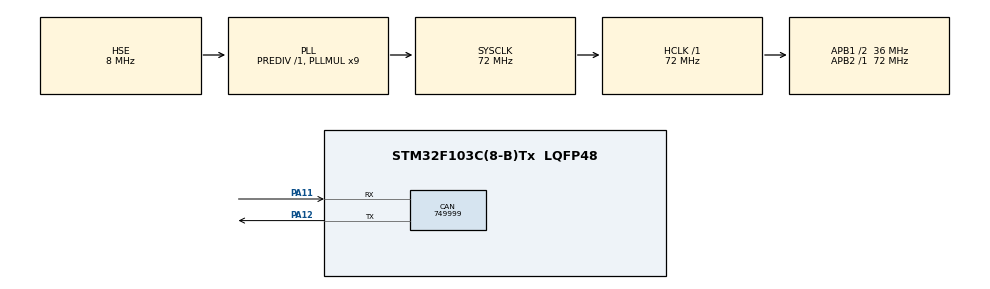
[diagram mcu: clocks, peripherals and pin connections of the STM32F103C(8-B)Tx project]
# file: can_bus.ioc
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CAN.CalculateBaudRate=749999
CAN.CalculateTimeBit=1333
CAN.CalculateTimeQuantum=444.44444444444446
Mcu.Family=STM32F1
Mcu.Name=STM32F103C(8-B)Tx
Mcu.Package=LQFP48
NVIC.CAN1_RX1_IRQn=true\:0\:0\:false\:false\:true\:true\:true\:true
NVIC.CAN1_SCE_IRQn=true\:0\:0\:false\:false\:true\:true\:true\:true
NVIC.PriorityGroup=NVIC_PRIORITYGROUP_4
NVIC.USB_HP_CAN1_TX_IRQn=true\:0\:0\:false\:false\:true\:true\:true\:true
NVIC.USB_LP_CAN1_RX0_IRQn=true\:0\:0\:false\:false\:true\:true\:true\:true
PA11.Mode=CAN_Activate
PA11.Signal=CAN_RX
PA12.Mode=CAN_Activate
PA12.Signal=CAN_TX
PC14-OSC32_IN.Mode=LSE-External-Oscillator
PC14-OSC32_IN.Signal=RCC_OSC32_IN
PC15-OSC32_OUT.Mode=LSE-External-Oscillator
PC15-OSC32_OUT.Signal=RCC_OSC32_OUT
PD0-OSC_IN.Mode=HSE-External-Oscillator
PD0-OSC_IN.Signal=RCC_OSC_IN
PD1-OSC_OUT.Mode=HSE-External-Oscillator
PD1-OSC_OUT.Signal=RCC_OSC_OUT
ProjectManager.HeapSize=0x200
ProjectManager.StackSize=0x400
ProjectManager.TargetToolchain=STM32CubeIDE
RCC.AHBFreq_Value=72000000
RCC.APB1CLKDivider=RCC_HCLK_DIV2
RCC.APB1Freq_Value=36000000
RCC.APB1TimFreq_Value=72000000
RCC.APB2Freq_Value=72000000
RCC.APB2TimFreq_Value=72000000
RCC.HCLKFreq_Value=72000000
RCC.PLLMUL=RCC_PLL_MUL9
RCC.PLLSourceVirtual=RCC_PLLSOURCE_HSE
RCC.SYSCLKFreq_VALUE=72000000
RCC.SYSCLKSource=RCC_SYSCLKSOURCE_PLLCLK
RCC.USBFreq_Value=72000000
VP_SYS_VS_ND.Mode=No_Debug
board=custom

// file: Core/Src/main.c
/* USER CODE BEGIN Header */
/**
  ******************************************************************************
  * @file           : main.c
  * @brief          : Main program body
  ******************************************************************************
  * @attention
  *
  * Copyright (c) 2022 STMicroelectronics.
  * All rights reserved.
  *
  * This software is licensed under terms that can be found in the LICENSE file
  * in the root directory of this software component.
  * If no LICENSE file comes with this software, it is provided AS-IS.
  *
  ******************************************************************************
  */
/* USER CODE END Header */
#include "main.h"

/* USER CODE BEGIN Includes */
//1. In reference manual we find CAN1 as master and CAN2 as slave. This is misleading as CAN bus is multi-master terminology.
//Here CAN1 referred as master because CAN2 does not have direct acess to SRAM.
//2. If we want to use CAN2 than we have to initialize CAN1 first.
//3. There are three transmit mailboxes and three receive fifo. Each mailboxes and receive fifo can hold three messages at the same time.
//4. Silent Mode: CAN tx is always maintained to recessive state. Tx line looped back to rx line. It just listens and doesn't change the bus sate
//by putting dominant bit.
//5. Loopback mode: can transmit frames on the bus. Frame looped back to the Rx line internally. Rx is disconnected from
//the bus. It does not listen to the bus. This mode ignores NACK and does not retransmit.
//6. Silent + loop back mode : both line disconnected from the bus. neither transmit nor listen to the bus. Tx line internally looped
//backed to rx line.
//7. Acceptance filter: reduces interrupt overhead. There are 28 filter banks. and each bank have two regitsters.
// Accept frames only if first 3 msb bits of the standard indenifier are 1s
// Filter bank 0: FB0_R1 : configurre as Mask mode
// Idenfifier register: 111xxxxxxxx(32:21) : fb0_r1 (filter_id_high:filter_id_low)
// Mask register: 111xxxxxxxx(32:21) : fb1_r1 (filter_mask_id_high:filter_mask_id_low)

//Accept frame only if first 3 msb bits are 0 and first 2 lsbs are 1.
//Identifier: 000xxxxxx11 : mask mode
//Mask regist : 111xxxxxx11

//Accept frame with exactly node 0x650 or 0x698
//List/Id mode
// Identifier1 : 0x650
// Identifier2: 0x698

//Accept only request frame
//set RTR bit recessive in identifier and mask register in mask mode.

//
//8. CAN CONTROLLER CAN GENERATE INTERRUPTS IN FOUR CASES
//transmit request completed
//frame received in rxfifo0
//frame received in rxfifo1
//during can status change or error
//there are 4 interrupt vectors are dedicated to each CAN controller in the stm32.

//RM0008 Rev 21 673/1136
//RM0008 Controller area network (bxCAN)
//698
//Figure 236. Event flags and interrupt generation
// The transmit interrupt can be generated by the following events:
//– Transmit mailbox 0 becomes empty, RQCP0 bit in the CAN_TSR register set.
//– Transmit mailbox 1 becomes empty, RQCP1 bit in the CAN_TSR register set.
//– Transmit mailbox 2 becomes empty, RQCP2 bit in the CAN_TSR register set.
// The FIFO 0 interrupt can be generated by the following events:
//– Reception of a new message, FMP0 bits in the CAN_RF0R register are not ‘00’.
//– FIFO0 full condition, FULL0 bit in the CAN_RF0R register set.
//– FIFO0 overrun condition, FOVR0 bit in the CAN_RF0R register set.
// The FIFO 1 interrupt can be generated by the following events:
//– Reception of a new message, FMP1 bits in the CAN_RF1R register are not ‘00’.
//– FIFO1 full condition, FULL1 bit in the CAN_RF1R register set.
//– FIFO1 overrun condition, FOVR1 bit in the CAN_RF1R register set.
// The error and status change interrupt can be generated by the following events:
//– Error condition, for more details on error conditions refer to the CAN Error Status.
//Wakeup condition, SOF monitored on the CAN Rx signal.
//– Entry into Sleep mode
//register (CAN_ESR).
/* USER CODE END Includes */

 CAN_HandleTypeDef hcan;

/* USER CODE BEGIN PV */
void CAN_Tx(void);
/* USER CODE END PV */

void SystemClock_Config(void);
static void MX_GPIO_Init(void);
static void MX_CAN_Init(void);

/* USER CODE BEGIN 0 */
void CAN_Tx()
{
	CAN_TxHeaderTypeDef TxHeader;
	uint32_t TxMailbox = 0;
	uint8_t message[5] = {1,2,3,4,5};

	TxHeader.DLC = 5;
	TxHeader.StdId = 0x780;
	TxHeader.IDE = CAN_ID_STD;
	TxHeader.RTR = CAN_RTR_DATA;

	if (HAL_CAN_AddTxMessage(&hcan,&TxHeader,message,&TxMailbox) != HAL_OK)
	{
		//Error_handler();
	}

	//while (HAL_CAN_IsTxMessagePending(&hcan,TxMailbox)); //waits unitll it transmit // polling mode
}

void CAN_Tx_Request()
{
	CAN_TxHeaderTypeDef TxHeader;
	uint32_t TxMailbox = 0;
	uint8_t message[5] = {1,2,3,4,5};//no meaning of data in case of data frame

	TxHeader.DLC = 2; //request two bytes of reply
	TxHeader.StdId = 0x780;
	TxHeader.IDE = CAN_ID_STD;
	TxHeader.RTR = CAN_RTR_REMOTE;

	if (HAL_CAN_AddTxMessage(&hcan,&TxHeader,&message[0],&TxMailbox) != HAL_OK)
	{
		//Error_handler();
	}

	//while (HAL_CAN_IsTxMessagePending(&hcan,TxMailbox)); //waits unitll it transmit // polling mode
}

//void CAN_Rx()
//{
//	CAN_RxHeaderTypeDef RxHeader;
//	uint8_t rcvd_data[8];
//
//	while (! HAL_CAN_GetRxFifoFillLevel(&hcan,CAN_RX_FIFO0));
//
//	if (HAL_CAN_GetRxMessage(&hcan,CAN_RX_FIFO0,&RxHeader,rcvd_data) != HAL_OK)
//	{
//		//handle the error
//	}
//}

void CAN_Filter()
{
	CAN_FilterTypeDef can_filter_init;

	can_filter_init.FilterActivation = ENABLE;
	can_filter_init.FilterBank = 0;
	can_filter_init.FilterFIFOAssignment = CAN_RX_FIFO0;
	can_filter_init.FilterIdHigh = 0;
	can_filter_init.FilterIdLow = 0;
	can_filter_init.FilterMaskIdHigh = 0;
	can_filter_init.FilterMaskIdLow = 0;
	can_filter_init.FilterMode = CAN_FILTERMODE_IDMASK;
	can_filter_init.FilterScale = CAN_FILTERSCALE_32BIT;

	if (HAL_CAN_ConfigFilter(&hcan,&can_filter_init) != HAL_OK)
	{
		//handle the error
	}

}

void HAL_CAN_TxMailbox0CompleteCallback(CAN_HandleTypeDef *hcan)
{
	//we don't know which mail box will be used to transmit
}
void HAL_CAN_TxMailbox1CompleteCallback(CAN_HandleTypeDef *hcan)
{

}
void HAL_CAN_TxMailbox2CompleteCallback(CAN_HandleTypeDef *hcan)
{

}
void HAL_CAN_RxFifo0MsgPendingCallback(CAN_HandleTypeDef *hcan)
{
	CAN_RxHeaderTypeDef RxHeader;
	uint8_t rcvd_data[8];
	if (HAL_CAN_GetRxMessage(hcan,CAN_RX_FIFO0,&RxHeader,rcvd_data) != HAL_OK)
	{
		//handle the error
	}
	if (RxHeader.StdId == 0x700 && RxHeader.RTR == 0)
	{
		//this is a data frame
		//do something using rcvd_data
	}
	else if (RxHeader.StdId == 0x710 && RxHeader.RTR == 1)
	{
		//this is a remote frame
		//send response
	}

}
void HAL_CAN_ErrorCallback(CAN_HandleTypeDef *hcan)
{
//handle the error
}

/* USER CODE END 0 */

int main(void)
{

  /* MCU Configuration--------------------------------------------------------*/

  /* Reset of all peripherals, Initializes the Flash interface and the Systick. */
  HAL_Init();

  /* Configure the system clock */
  SystemClock_Config();

  /* Initialize all configured peripherals */
  MX_GPIO_Init();
  MX_CAN_Init();
  /* USER CODE BEGIN 2 */
  // MX_CAN_Init() function will configure can controller to Initialization state

  CAN_Filter();//this function should be called in initialization state // This filter is configured to accept all frames
  if(HAL_CAN_ActivateNotification(&hcan,CAN_IT_TX_MAILBOX_EMPTY | CAN_IT_RX_FIFO0_MSG_PENDING | CAN_IT_BUSOFF) != HAL_OK)
  {
	  //handle the error.
  }
  if (HAL_CAN_Start(&hcan) != HAL_OK) // this will switch can controller to Initialization mode to normal mode
  {
	  //handle the error.
  }

  CAN_Tx();//for transmission and reception can controller should be in normal mode (look CAN NORMAL MODE is different than this)
  //CAN_Rx();

  /* USER CODE END 2 */

  /* Infinite loop */
  while (1)
  {

  }
}

void SystemClock_Config(void)
{
  RCC_OscInitTypeDef RCC_OscInitStruct = {0};
  RCC_ClkInitTypeDef RCC_ClkInitStruct = {0};

  /** Initializes the RCC Oscillators according to the specified parameters
  * in the RCC_OscInitTypeDef structure.
  */
  RCC_OscInitStruct.OscillatorType = RCC_OSCILLATORTYPE_HSE;
  RCC_OscInitStruct.HSEState = RCC_HSE_ON;
  RCC_OscInitStruct.HSEPredivValue = RCC_HSE_PREDIV_DIV1;
  RCC_OscInitStruct.HSIState = RCC_HSI_ON;
  RCC_OscInitStruct.PLL.PLLState = RCC_PLL_ON;
  RCC_OscInitStruct.PLL.PLLSource = RCC_PLLSOURCE_HSE;
  RCC_OscInitStruct.PLL.PLLMUL = RCC_PLL_MUL9;
  if (HAL_RCC_OscConfig(&RCC_OscInitStruct) != HAL_OK)
  {
    Error_Handler();
  }

  /** Initializes the CPU, AHB and APB buses clocks
  */
  RCC_ClkInitStruct.ClockType = RCC_CLOCKTYPE_HCLK|RCC_CLOCKTYPE_SYSCLK
                              |RCC_CLOCKTYPE_PCLK1|RCC_CLOCKTYPE_PCLK2;
  RCC_ClkInitStruct.SYSCLKSource = RCC_SYSCLKSOURCE_PLLCLK;
  RCC_ClkInitStruct.AHBCLKDivider = RCC_SYSCLK_DIV1;
  RCC_ClkInitStruct.APB1CLKDivider = RCC_HCLK_DIV2;
  RCC_ClkInitStruct.APB2CLKDivider = RCC_HCLK_DIV1;

  if (HAL_RCC_ClockConfig(&RCC_ClkInitStruct, FLASH_LATENCY_2) != HAL_OK)
  {
    Error_Handler();
  }
}

static void MX_CAN_Init(void)
{

  /* USER CODE BEGIN CAN_Init 0 */
//	  hcan.Instance = CAN1;
//	  hcan.Init.Prescaler = 9;
//	  hcan.Init.Mode = CAN_MODE_LOOPBACK;
//	  hcan.Init.SyncJumpWidth = CAN_SJW_1TQ;
//	  hcan.Init.TimeSeg1 = CAN_BS1_13TQ;
//	  hcan.Init.TimeSeg2 = CAN_BS2_1TQ; //here speed is 250k at 36mhz clock cycle
//	  hcan.Init.TimeTriggeredMode = DISABLE;
//	  hcan.Init.AutoBusOff = ENABLE;// once the error counter reaches certain limit the can controller will be off hence enabling this will start recovery of can bus (re-initialize)
//	  hcan.Init.AutoWakeUp = DISABLE;//enabling this will generate interrupt upon receiving SOF of CAN frame
//	  hcan.Init.AutoRetransmission = ENABLE; //Enable auto retransmission
//	  hcan.Init.ReceiveFifoLocked = DISABLE; // if it is disabled once receive fifo is full the next incoming message will overwrite the prev one and if it is enabled new messages will be discarded.
//	  hcan.Init.TransmitFifoPriority = DISABLE;//defines priority of mailboxes messages (one mailbox can hold three messages) // if 0 then priority is driven by Identifier // if 1 then priority driven by request order

//	  if (HAL_CAN_Init(&hcan) != HAL_OK)
//	  {
//	    Error_Handler();
//	  }

  /* USER CODE END CAN_Init 0 */

  hcan.Instance = CAN1;
  hcan.Init.Prescaler = 16;
  hcan.Init.Mode = CAN_MODE_NORMAL;
  hcan.Init.SyncJumpWidth = CAN_SJW_1TQ;
  hcan.Init.TimeSeg1 = CAN_BS1_1TQ;
  hcan.Init.TimeSeg2 = CAN_BS2_1TQ;
  hcan.Init.TimeTriggeredMode = DISABLE;
  hcan.Init.AutoBusOff = DISABLE;
  hcan.Init.AutoWakeUp = DISABLE;
  hcan.Init.AutoRetransmission = DISABLE;
  hcan.Init.ReceiveFifoLocked = DISABLE;
  hcan.Init.TransmitFifoPriority = DISABLE;
  if (HAL_CAN_Init(&hcan) != HAL_OK)
  {
    Error_Handler();
  }

}

static void MX_GPIO_Init(void)
{

  /* GPIO Ports Clock Enable */
  __HAL_RCC_GPIOC_CLK_ENABLE();
  __HAL_RCC_GPIOD_CLK_ENABLE();
  __HAL_RCC_GPIOA_CLK_ENABLE();

}

void Error_Handler(void)
{
  __disable_irq();
  while (1)
  {
  }
}
